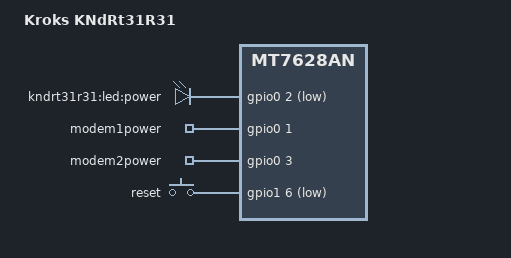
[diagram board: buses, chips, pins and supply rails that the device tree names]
#include "mt7628an_kroks.dtsi"

#include <dt-bindings/input/input.h>
#include <dt-bindings/gpio/gpio.h>

/ {
	compatible = "kroks,kndrt31r31", "mediatek,mt7628an-soc";
	model = "Kroks KNdRt31R31";

	aliases {
		led-boot = &led_power;
		led-failsafe = &led_power;
		led-running = &led_power;
		led-upgrade = &led_power;
	};

	leds {
		compatible = "gpio-leds";

		led_power: power {
			label = "kndrt31r31:led:power";
			gpios = <&gpio0 2 GPIO_ACTIVE_LOW>;
		};
	};

	gpio_export {
		compatible = "gpio-export";
		#size-cells = <0>;

		modem1power {
			gpio-export,name = "modem1power";
			gpio-export,output = <1>;
			gpios = <&gpio0 1 GPIO_ACTIVE_HIGH>;
		};

		modem2power {
			gpio-export,name = "modem2power";
			gpio-export,output = <1>;
			gpios = <&gpio0 3 GPIO_ACTIVE_HIGH>;
		};
	};

	keys {
		compatible = "gpio-keys";

		reset {
			label = "reset";
			gpios = <&gpio1 6 GPIO_ACTIVE_LOW>;
			linux,code = <KEY_RESTART>;
		};
	};
};

&state_default {
	gpio {
		ralink,group = "i2s", "wdt";
		ralink,function = "gpio";
	};

	p3led_an {
		ralink,group = "p3led_an";
		ralink,function = "p3led_an";
	};

	p4led_an {
		ralink,group = "p4led_an";
		ralink,function = "p4led_an";
	};
};

&wmac {
	status = "disabled";
};
